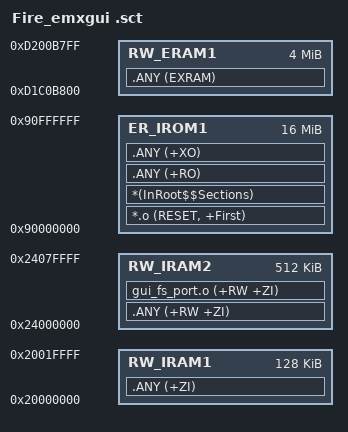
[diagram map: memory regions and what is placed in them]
; *************************************************************
; *** Scatter-Loading Description File generated by uVision ***
; *************************************************************

LR_IROM1 0x90000000 0x01000000  {    ; load region size_region
  ER_IROM1 0x90000000 0x01000000  {  ; load address = execution address
   *.o (RESET, +First)
   *(InRoot$$Sections)
   .ANY (+RO)
   .ANY (+XO)
  }
  RW_IRAM1 0x20000000 0x00020000  {  ; RW data
   .ANY (+ZI)
  }
  RW_IRAM2 0x24000000 0x00080000  {
   .ANY (+RW +ZI)
   gui_fs_port.o (+RW +ZI);由于DMA访问权限,功能要正常使用的话,缓冲区要放在非TCM区中
  }  
  RW_ERAM1 (0xd18bb800+0x00350000) 0x00400000 {  ; 外部SDRAM  //100000
;    *.o (HEAP)          选择堆区
   .ANY (EXRAM)				;选择EXRAM节区
  }
}
